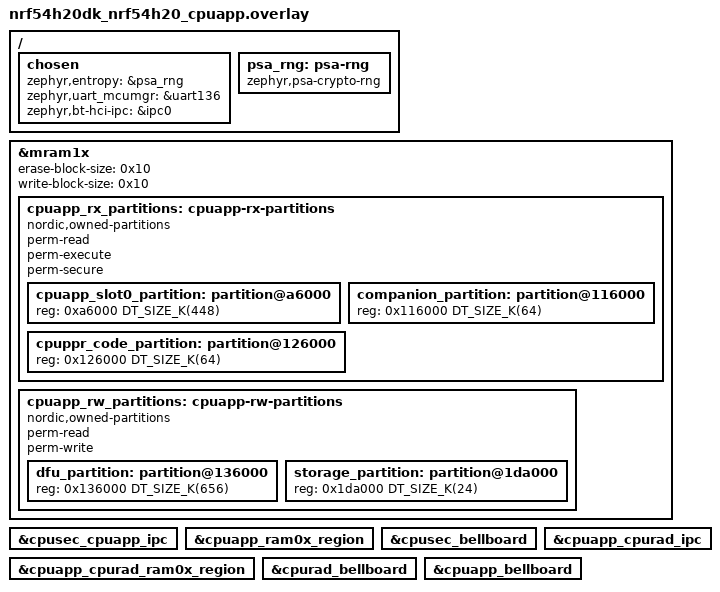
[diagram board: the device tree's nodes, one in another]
/*
 * Copyright (c) 2023 Nordic Semiconductor ASA
 *
 * SPDX-License-Identifier: LicenseRef-Nordic-5-Clause
 */

/ {
	chosen {
		zephyr,entropy = &psa_rng;
		zephyr,uart_mcumgr = &uart136;
		zephyr,bt-hci-ipc = &ipc0;
	};

	psa_rng: psa-rng {
		compatible = "zephyr,psa-crypto-rng";
		status = "okay";
	};
};

/delete-node/ &cpuapp_rx_partitions;
/delete-node/ &cpuapp_rw_partitions;

&mram1x {
	erase-block-size = < 0x10 >;
	/* Hardcoded inside the soc_flash_nrf_mram.c (MRAM_WORD_SIZE) */
	write-block-size = < 0x10 >;

	cpuapp_rx_partitions: cpuapp-rx-partitions {
		compatible = "nordic,owned-partitions", "fixed-partitions";
		status = "okay";
		perm-read;
		perm-execute;
		perm-secure;
		#address-cells = <1>;
		#size-cells = <1>;

		cpuapp_slot0_partition: partition@a6000 {
			reg = <0xa6000 DT_SIZE_K(448)>;
		};

		companion_partition: partition@116000 {
			reg = <0x116000 DT_SIZE_K(64)>;
		};

		cpuppr_code_partition: partition@126000 {
			reg = <0x126000 DT_SIZE_K(64)>;
		};
	};

	cpuapp_rw_partitions: cpuapp-rw-partitions {
		compatible = "nordic,owned-partitions", "fixed-partitions";
		status = "okay";
		perm-read;
		perm-write;
		#address-cells = < 0x1 >;
		#size-cells = < 0x1 >;

		dfu_partition: partition@136000 {
			reg = < 0x136000 DT_SIZE_K(656) >;
		};

		storage_partition: partition@1da000 {
			reg = < 0x1da000 DT_SIZE_K(24) >;
		};
	};
};

&cpusec_cpuapp_ipc {
	status = "okay";
};

&cpuapp_ram0x_region {
	status = "okay";
};

&cpusec_bellboard {
	status = "okay";
};

ipc0: &cpuapp_cpurad_ipc {
	status = "okay";
};

&cpuapp_cpurad_ram0x_region {
	status = "okay";
};

&cpurad_bellboard {
	status = "okay";
};

&cpuapp_bellboard {
	status = "okay";
};
